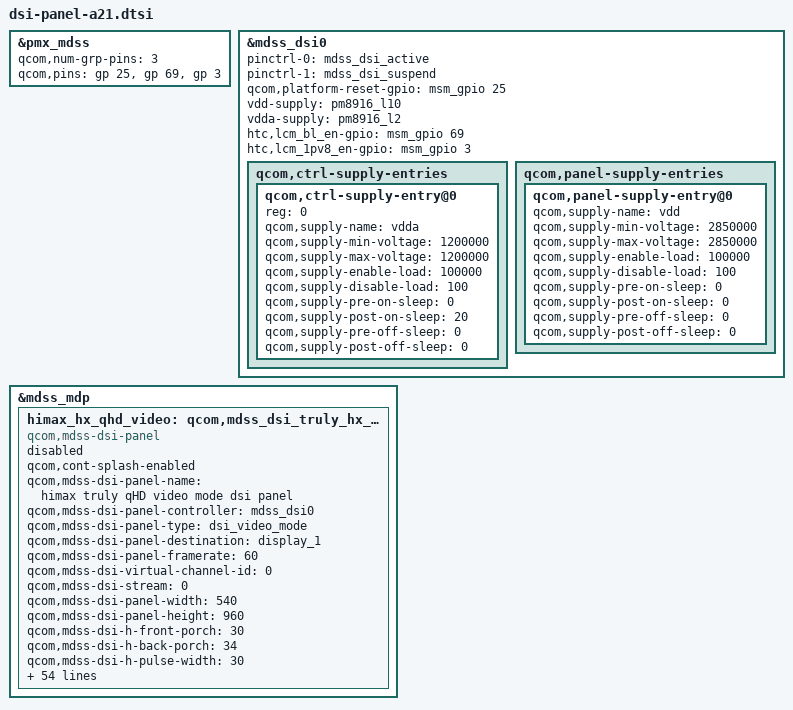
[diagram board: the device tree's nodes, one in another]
/* Copyright (c) 2013, The Linux Foundation. All rights reserved.
 *
 * This program is free software; you can redistribute it and/or modify
 * it under the terms of the GNU General Public License version 2 and
 * only version 2 as published by the Free Software Foundation.
 *
 * This program is distributed in the hope that it will be useful,
 * but WITHOUT ANY WARRANTY; without even the implied warranty of
 * MERCHANTABILITY or FITNESS FOR A PARTICULAR PURPOSE.  See the
 * GNU General Public License for more details.
 */

/*---------------------------------------------------------------------------
 * This file is autogenerated file using gcdb parser. Please do not edit it.
 * Update input XML file to add a new entry or update variable in this file
 * VERSION = "1.0"
 *---------------------------------------------------------------------------*/
&pmx_mdss {
	qcom,num-grp-pins = <3>;
	qcom,pins = <&gp 25>, <&gp 69>, <&gp 3>;
};

&mdss_dsi0 {
	pinctrl-names = "mdss_default", "mdss_sleep";
	pinctrl-0 = <&mdss_dsi_active>;
	pinctrl-1 = <&mdss_dsi_suspend>;

	qcom,platform-reset-gpio = <&msm_gpio 25 0>;
	vdd-supply = <&pm8916_l10>;
	vdda-supply = <&pm8916_l2>;
	htc,lcm_bl_en-gpio = <&msm_gpio 69 0>;
	htc,lcm_1pv8_en-gpio = <&msm_gpio 3 0>;

	qcom,ctrl-supply-entries {
		#address-cells = <1>;
		#size-cells = <0>;

		qcom,ctrl-supply-entry@0 {
			reg = <0>;
			qcom,supply-name = "vdda";
			qcom,supply-min-voltage = <1200000>;
			qcom,supply-max-voltage = <1200000>;
			qcom,supply-enable-load = <100000>;
			qcom,supply-disable-load = <100>;
			qcom,supply-pre-on-sleep = <0>;
			qcom,supply-post-on-sleep = <20>;
			qcom,supply-pre-off-sleep = <0>;
			qcom,supply-post-off-sleep = <0>;
		};
	};

	qcom,panel-supply-entries {
		#address-cells = <1>;
		#size-cells = <0>;

		qcom,panel-supply-entry@0 {
			qcom,supply-name = "vdd";
			qcom,supply-min-voltage = <2850000>;
			qcom,supply-max-voltage = <2850000>;
			qcom,supply-enable-load = <100000>;
			qcom,supply-disable-load = <100>;
			qcom,supply-pre-on-sleep = <0>;
			qcom,supply-post-on-sleep = <0>;
			qcom,supply-pre-off-sleep = <0>;
			qcom,supply-post-off-sleep = <0>;
		};
	};
};

&mdss_mdp {
	himax_hx_qhd_video: qcom,mdss_dsi_truly_hx_qHD_video {
		compatible = "qcom,mdss-dsi-panel";
		status = "disabled";
		qcom,cont-splash-enabled;
		qcom,mdss-dsi-panel-name = "himax truly qHD video mode dsi panel";
		qcom,mdss-dsi-panel-controller = <&mdss_dsi0>;
		qcom,mdss-dsi-panel-type = "dsi_video_mode";

		qcom,mdss-dsi-panel-destination = "display_1";
		qcom,mdss-dsi-panel-framerate = <60>;
		qcom,mdss-dsi-virtual-channel-id = <0>;
		qcom,mdss-dsi-stream = <0>;
		qcom,mdss-dsi-panel-width = <540>;
		qcom,mdss-dsi-panel-height = <960>;
		qcom,mdss-dsi-h-front-porch = <30>;
		qcom,mdss-dsi-h-back-porch = <34>;
		qcom,mdss-dsi-h-pulse-width = <30>;
		qcom,mdss-dsi-h-sync-skew = <0>;
		qcom,mdss-dsi-v-back-porch = <13>;
		qcom,mdss-dsi-v-front-porch = <8>;
		qcom,mdss-dsi-v-pulse-width = <5>;
		qcom,mdss-dsi-h-left-border = <0>;
		qcom,mdss-dsi-h-right-border = <0>;
		qcom,mdss-dsi-v-top-border = <0>;
		qcom,mdss-dsi-v-bottom-border = <0>;
		qcom,mdss-dsi-bpp = <24>;
		qcom,mdss-dsi-color-order = <0>;
		qcom,mdss-dsi-underflow-color = <0xff>;
		qcom,mdss-dsi-border-color = <0>;
		qcom,mdss-dsi-on-command = [
			39 01 00 00 01 00 04 B9 FF 83 89
			39 01 00 00 01 00 08 BA 41 93 00 16 A4 00 18
			39 01 00 00 01 00 02 C6 08
			39 01 00 00 01 00 02 CC 02
			39 01 00 00 01 00 03 C0 43 15

			39 01 00 00 01 00 14 B1 00 00 04 E3 9E 10 11 6F EF 28 30 23 23 42 00 58 F2 20 00
			39 01 00 00 01 00 04 DE 05 58 10
			39 01 00 00 0A 00 08 B2 00 00 78 08 03 00 80

			39 01 00 00 0A 00 18 B4 80 08 00 32 10 00 00 00 00 00 00 00 37 0A 40 04 37 0A 40 14 FF FF 0A

			39 01 00 00 0A 00 31 D5 00 00 4C 00 01 00 00 00 60 00 99 88 99 88 88 32 88 10 88 76 88 54 10 32 88 88 88 88 88 88 99 88 99 88 45 88 67 88 01 88 23 23 01 88 88 88 88 88

			39 01 00 00 05 00 23 E0 00 05 09 2A 2E 3F 15 37 05 0B 10 12 14 12 13 11 19 00 04 08 2A 2F 3F 16 38 06 0C 0E 11 13 12 13 10 17
			39 01 00 00 01 00 80 C1 01 00 0B 14 1A 24 2B 33 3B 44 4B 54 5C 64 6D 75 7D 85 8D 95 9E A7 B0 B8 C0 C8 CD D5 DD E4 EB F4 F8 FF 12 3B 72 92 5D 00 73 B3 C0 00 08 11 18 20 27 2F 37 3E 46 4D 55 5C 64 6C 74 7B 82 8A 92 9A A2 AB B4 BB C4 CB D1 DA E3 EB F5 FE 20 68 81 F4 B8 64 E3 51 C0 00 06 0D 15 1D 25 2D 35 3C 44 4B 53 5A 62 6A 71 79 80 87 8E 96 9D A5 AD B4 BC C4 CA D0 D8 E1 E8 F0 00 AC D5 F2 1B 74 C6 A4 00

			39 01 00 00 01 00 02 35 01
			39 01 00 00 01 00 0A C9 0F 00 01 10 00 00 00 01 3A
			/* CABC Command Start */
			39 01 00 00 01 00 02 55 02
			39 01 00 00 01 00 02 5E 11
			39 01 00 00 01 00 0A CA 2D 27 26 25 24 22 21 20 20
			39 01 00 00 01 00 23 CE 00 10 10 10 10 16 16 16 16 16 16 16 16 16 00 00 00 00 00 00 00 00 00 00 00 00 00 00 00 00 00 00 00 00
			/* CABC Command End */
			39 01 00 00 01 00 02 53 2C
			39 01 00 00 01 00 02 E6 00
			39 01 00 00 01 00 02 E3 01
			05 01 00 00 C8 00 02 11 00
			];
		qcom,mdss-dsi-off-command = [05 01 00 00 01 00 02 28 00
					05 01 00 00 78 00 02 10 00];
		qcom,mdss-dsi-on-command-state = "dsi_lp_mode";
		qcom,mdss-dsi-off-command-state = "dsi_hs_mode";
		qcom,mdss-dsi-h-sync-pulse = <1>;
		qcom,mdss-dsi-traffic-mode = <1>;
		qcom,mdss-dsi-bllp-eof-power-mode;
		qcom,mdss-dsi-lane-map = <0>;
		qcom,mdss-dsi-bllp-power-mode;
		qcom,mdss-dsi-lane-0-state;
		qcom,mdss-dsi-lane-1-state;
		qcom,mdss-dsi-panel-timings =  [87 20 12 00 40 44 16 22 17 03 04 00];
		qcom,mdss-dsi-t-clk-post = <0x1f>;
		qcom,mdss-dsi-t-clk-pre = <0x39>;
		qcom,mdss-dsi-bl-min-level = <1>;
		qcom,mdss-dsi-bl-max-level = <255>;
		qcom,mdss-dsi-dma-trigger = <0x04>;
		qcom,mdss-dsi-mdp-trigger = <0x0>;
		qcom,mdss-dsi-bl-pmic-control-type = "bl_ctrl_dcs";

		qcom,display-on-cmds = [05 01 00 00 64 00 02 29 00];
		qcom,mdss-dsi-default-command-state = "dsi_hs_mode";
		qcom,mdss-pan-physical-width-dimension = <61>;
		qcom,mdss-pan-physical-height-dimension = <110>;
		qcom,mdss-shrink-pwm = <16 113 255>;
		qcom,mdss-shrink-pwm-power-hack = <16 113 255>;
		qcom,mdss-dsi-lp11-init;
		htc,mdss-camera-blk = <213>;
		htc,panel-id=<1>;
		htc,cabc-off-cmds = [
			39 01 00 00 01 00 02 55 00
			];
		htc,cabc-ui-cmds = [
			39 01 00 00 05 00 02 55 02
			39 01 00 00 01 00 02 5E 11
			39 01 00 00 01 00 0A CA 2D 27 26 25 24 22 21 20 20
			39 01 00 00 01 00 23 CE 00 10 10 10 10 16 16 16 16 16 16 16 16 16 00 00 00 00 00 00 00 00 00 00 00 00 00 00 00 00 00 00 00 00
			];
		htc,cabc-video-cmds = [
			39 01 00 00 05 00 02 55 03
			39 01 00 00 01 00 02 5E 11
			39 01 00 00 01 00 0A CA 40 30 2F 2E 2D 26 22 20 20
			39 01 00 00 01 00 23 CE 00 18 1A 1A 20 20 20 20 28 28 28 28 28 28 28 28 30 30 30 30 30 30 30 30 30 30 30 30 30 30 30 30 30 00
			];
		htc,dimming-on-cmds = [39 01 00 00 00 00 02 53 2C];
	};
};
